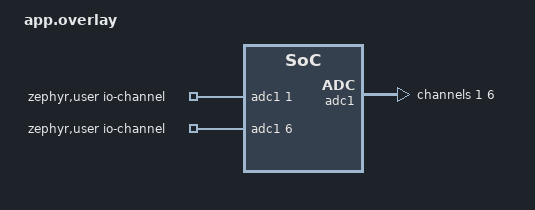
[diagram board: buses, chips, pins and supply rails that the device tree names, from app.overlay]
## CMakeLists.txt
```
cmake_minimum_required(VERSION 3.20.0)
set(BOARD stm32f4_disco)
set(BOARD_FLASH_RUNNER openocd)
find_package(Zephyr REQUIRED HINTS $ENV{ZEPHYR_BASE})
project(blinky_led)

target_sources(app PRIVATE src/main.c)
target_sources(app PRIVATE src/threadA.c)
target_sources(app PRIVATE src/threadB.c)
```

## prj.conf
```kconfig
CONFIG_GPIO=y
CONFIG_ADC=y
CONFIG_DEBUG_OPTIMIZATIONS=y
```

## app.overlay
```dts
/*
 * Copyright (c) 2025 Ajith Anandhan
 *
 * SPDX-License-Identifier: Apache-2.0
 */

/ {
	zephyr,user {
		io-channels = <&adc1 1>, <&adc1 6>;
	};
};

&adc1 {
	status = "okay";

	#address-cells = <1>;
	#size-cells = <0>;

	channel@1 {
		reg = <1>;
		zephyr,gain = "ADC_GAIN_1";
		zephyr,reference = "ADC_REF_INTERNAL";
		zephyr,acquisition-time = <ADC_ACQ_TIME_DEFAULT>;
		zephyr,resolution = <12>;
	};

	channel@6 {
		reg = <6>;
		zephyr,gain = "ADC_GAIN_1";
		zephyr,reference = "ADC_REF_INTERNAL";
		zephyr,acquisition-time = <ADC_ACQ_TIME_DEFAULT>;
		zephyr,resolution = <12>;
	};
};
```

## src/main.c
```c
#include <zephyr/kernel.h>

#define STACK_SIZE 1024U

extern void Thread_B(void *, void *, void *);
extern void Thread_A(void *, void *, void *);

K_THREAD_DEFINE(thread_b, STACK_SIZE,
				Thread_B, NULL, NULL, NULL,
				3, 0, 0);

K_THREAD_DEFINE(thread_a, STACK_SIZE,
				Thread_A, NULL, NULL, NULL,
				44, 0, 0);
int main(void)
{
    return 0;
}
```

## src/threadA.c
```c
#include <zephyr/drivers/gpio.h>
#include <zephyr/kernel.h>


#define LED0_NODE DT_ALIAS(led0)

static const struct gpio_dt_spec ledGreen = GPIO_DT_SPEC_GET(LED0_NODE, gpios);


void Thread_A(void *dummy1, void *dummy2, void *dummy3)
{
    if (!gpio_is_ready_dt(&ledGreen)) 
    {
    }

    gpio_pin_configure_dt(&ledGreen, GPIO_OUTPUT_ACTIVE);
    
    while(1)
    {
        gpio_pin_toggle_dt(&ledGreen);

        k_msleep(2000);
    }
    
}
```

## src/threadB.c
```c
#include <zephyr/drivers/gpio.h>
#include <zephyr/drivers/adc.h>
#include <zephyr/kernel.h>

#define LED1_NODE DT_ALIAS(led1)

static const struct gpio_dt_spec ledOrange = GPIO_DT_SPEC_GET(LED1_NODE, gpios);

static const struct adc_dt_spec adc_channels[] =
{    
    ADC_DT_SPEC_GET_BY_IDX(DT_PATH(zephyr_user), 0),
    ADC_DT_SPEC_GET_BY_IDX(DT_PATH(zephyr_user), 1)
};
uint32_t bufArray[2];

struct adc_sequence sequences[] =
{
    {
        .buffer = &bufArray[0],
        .buffer_size = sizeof(uint32_t)
    },
    {
        .buffer = &bufArray[1],
        .buffer_size = sizeof(uint32_t)
    }

};


void Thread_B(void *dummy1, void *dummy2, void *dummy3)
{
    if (!gpio_is_ready_dt(&ledOrange)) 
    {
    }

    if(!adc_is_ready_dt(&adc_channels[0]))
    {

    }
    
    if(!adc_is_ready_dt(&adc_channels[1]))
    {
        
    }

    adc_channel_setup_dt(&adc_channels[0]);
    adc_channel_setup_dt(&adc_channels[1]);

    gpio_pin_configure_dt(&ledOrange, GPIO_OUTPUT_ACTIVE);

    (void)adc_sequence_init_dt(&adc_channels[0], &sequences[0]);
	(void)adc_sequence_init_dt(&adc_channels[1], &sequences[1]);
    
    while(1)
    {
        gpio_pin_toggle_dt(&ledOrange);

        adc_read_dt(&adc_channels[0], &sequences[0]);

        adc_read_dt(&adc_channels[1], &sequences[1]);

        k_msleep(500);
    }
    


}
```
